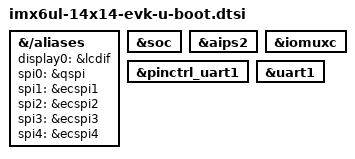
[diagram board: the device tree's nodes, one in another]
// SPDX-License-Identifier: GPL-2.0+
/*
 * Copyright 2018, 2023 NXP
 */

&{/aliases} {
	bootph-all;
	display0 = &lcdif;

	spi0 = &qspi;
	spi1 = &ecspi1;
	spi2 = &ecspi2;
	spi3 = &ecspi3;
	spi4 = &ecspi4;
};

&soc {
	bootph-pre-ram;
	bootph-all;
};

&aips2 {
	bootph-pre-ram;
	bootph-all;
};

&iomuxc {
	bootph-pre-ram;
	bootph-all;
};

&pinctrl_uart1 {
	bootph-pre-ram;
	bootph-all;
};

&uart1 {
	bootph-pre-ram;
	bootph-all;
};
